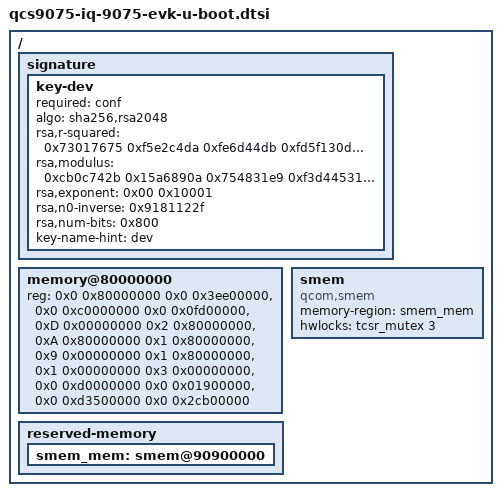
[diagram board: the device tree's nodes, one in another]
// SPDX-License-Identifier: BSD-3-Clause
/*
 * Copyright (c) Qualcomm Technologies, Inc. and/or its subsidiaries.
 */

/ {
	/* public key info */
	signature {
		key-dev {
			required = "conf";
			algo = "sha256,rsa2048";
			rsa,r-squared = <0x73017675 0xf5e2c4da 0xfe6d44db 0xfd5f130d 0x21863487
					 0x760d9432 0x716d1c9e 0x48188771 0xb8615df5 0x1ffbe68f
					 0x4d45141d 0x4d5354f7 0x988ea777 0xda26bba8 0xc20cd179
					 0x776088f3 0x8730a9e 0xde8b1549 0x850e4aeb 0xaff3c7a4
					 0xe0059835 0xf176e31c 0x6c4ab224 0x8d2ec933 0x22516414
					 0x2c748578 0x9d39de02 0x5363f7e8 0x1f3703ba 0xc6ed3922
					 0xb50e9dd2 0x6584b53d 0x70cfd586 0xd1a68465 0x41627667
					 0xd3fee952 0x900bca41 0x780c9469 0x366f396a 0x83c94e42
					 0x65c4211 0xc8538a5 0x18de0db 0x57af5098 0x5f2932d
					 0x461caa24 0x39913f72 0x4023aada 0xcff6e7ff 0xb5c8dbf5
					 0x13aca8f4 0x5209d2e2 0x1d8726c0 0x9e86daa0 0xfe4b73f9
					 0xefffc64d 0x5a2514d6 0x7b7b09ff 0xf16c50a2 0xf5d74ba8
					 0x686c4133 0x5c3991bc 0xe834e22a 0xb2103ced>;
			rsa,modulus =  <0xcb0c742b 0x15a6890a 0x754831e9 0xf3d44531 0xc306b115
					 0x34a3deb2 0x527c5bd5 0x828ed21f 0x5a46027a 0xa5381121
					 0x4031facd 0x81a666b 0x5867c4d5 0x4173c28c 0xdd70c148
					 0x1a475a15 0x51ea18f0 0x8bd44475 0x69409c1a 0x87a710a2
					 0x4d708e9f 0xbe0b4261 0xbb2881fd 0x1ee8a634 0x6e95abc0
					 0xbdba8ea4 0x76098be 0xcfb0df9c 0x5343e6be 0x11a946b8
					 0x9a1ee914 0x5ebf3344 0x11585e32 0x38cf1a79 0x77717525
					 0x9b6ff0aa 0xcb8aceb3 0x4ef36174 0xc007f358 0x16ca9b12
					 0xca323b49 0x7307e978 0x24ef6b72 0x2058810e 0x4bca7981
					 0xbfe9c2a6 0xa666d2d0 0xc7773a26 0xaabb51a2 0x118a4be1
					 0x58061ab0 0xe77aefca 0x1a5754f7 0x72a1d150 0x2eea3774
					 0x172a13d3 0xfa101874 0x7c7830a2 0xa0f15927 0x6b124d30
					 0xd0a8528f 0x4dae4b1e 0x693a03c8 0x6548b31>;
			rsa,exponent = <0x00 0x10001>;
			rsa,n0-inverse = <0x9181122f>;
			rsa,num-bits = <0x800>;
			key-name-hint = "dev";
		};
	};
	memory@80000000 {
		device_type = "memory";
		reg = <0x0 0x80000000 0x0 0x3ee00000>,
			<0x0 0xc0000000 0x0 0x0fd00000>,
			<0xD 0x00000000 0x2 0x80000000>,
			<0xA 0x80000000 0x1 0x80000000>,
			<0x9 0x00000000 0x1 0x80000000>,
			<0x1 0x00000000 0x3 0x00000000>,
			<0x0 0xd0000000 0x0 0x01900000>,
			<0x0 0xd3500000 0x0 0x2cb00000>;
	};

	reserved-memory {
		smem_mem: smem@90900000 {
			/delete-property/ compatible;
			/delete-property/ hwlocks;
		};
	};

	smem {
		compatible = "qcom,smem";
		memory-region = <&smem_mem>;
		hwlocks = <&tcsr_mutex 3>;
	};

};
